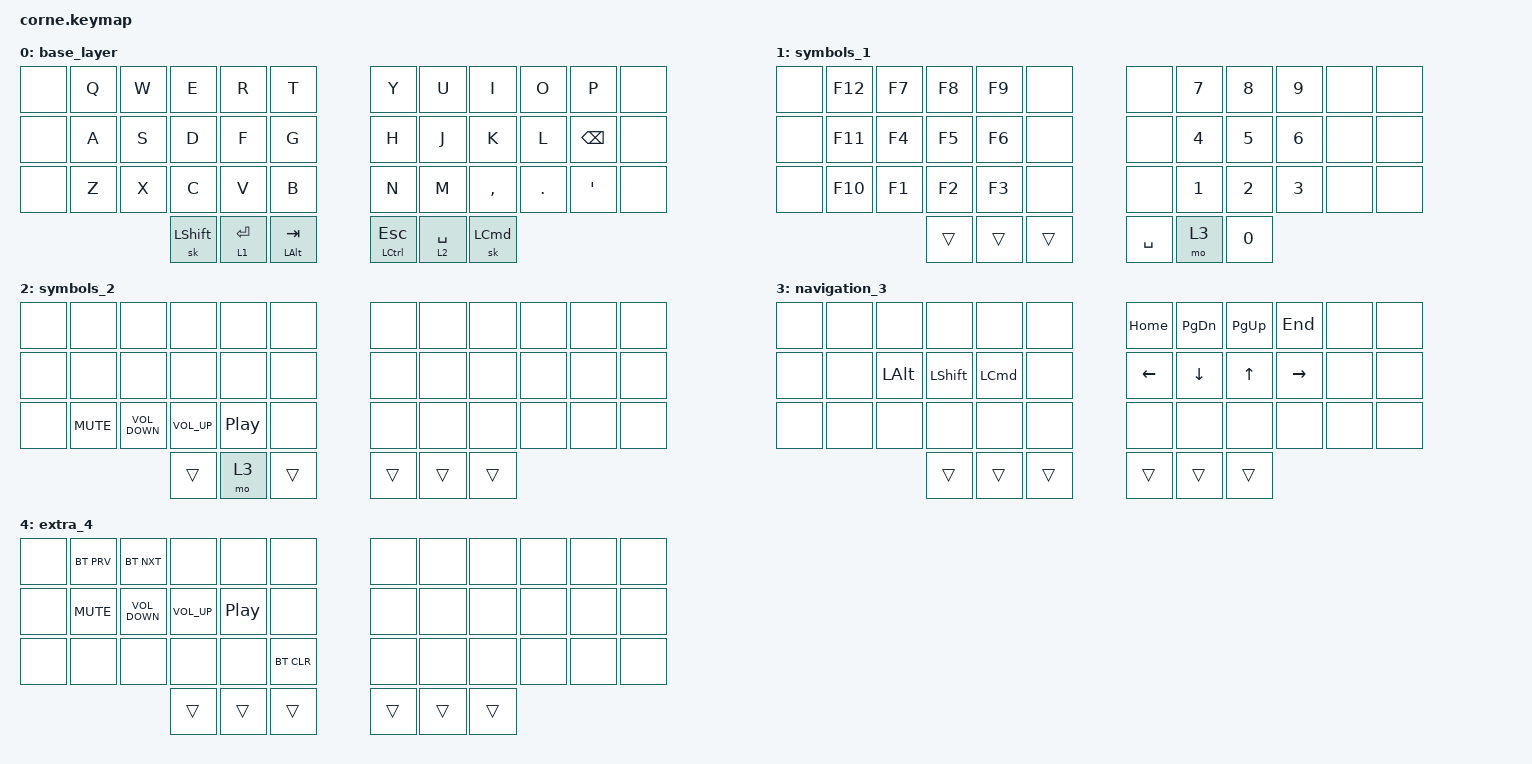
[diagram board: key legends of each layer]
/*
 *
 * SPDX-License-Identifier: MIT
 * test
 */

#include <behaviors.dtsi>
#include <dt-bindings/zmk/keys.h>
#include <dt-bindings/zmk/bt.h>
#include <dt-bindings/zmk/mouse.h>

&mmv {
  time-to-max-speed-ms = <400>;
  acceleration-exponent = <0>;
  delay-ms = <0>;
};

#define U_MOUSE_MOVE_MAX 1400

#undef MOVE_UP
#undef MOVE_DOWN
#undef MOVE_LEFT
#undef MOVE_RIGHT
#define MOVE_UP MOVE_VERT(-U_MOUSE_MOVE_MAX)
#define MOVE_DOWN MOVE_VERT(U_MOUSE_MOVE_MAX)
#define MOVE_LEFT MOVE_HOR(-U_MOUSE_MOVE_MAX)
#define MOVE_RIGHT MOVE_HOR(U_MOUSE_MOVE_MAX)

/ {
    macros {
        option_backspace: option_backspace {
            compatible = "zmk,behavior-macro";
            label = "option_backspace";
            #binding-cells = <0>;
            wait-ms = <0>;
            bindings =
                <&macro_press &kp LEFT_ALT>,
                <&macro_tap &kp BACKSPACE>,
                <&macro_release &kp LEFT_ALT>;
        };

        option_delete: option_delete {
            compatible = "zmk,behavior-macro";
            label = "option_delete";
            #binding-cells = <0>;
	        wait-ms = <0>;
            bindings =
                <&macro_press &kp LEFT_ALT>,
                <&macro_tap &kp DELETE>,
                <&macro_release &kp LEFT_ALT>;
        };

    	command_backspace: command_backspace{
            compatible = "zmk,behavior-macro";
            label = "command_backspace";
            #binding-cells = <0>;
            wait-ms = <0>;
            bindings =
                <&macro_press &kp LEFT_COMMAND>,
                <&macro_tap &kp BACKSPACE>,
                <&macro_release &kp LEFT_COMMAND>;
        };

	    command_delete: command_delete{
            compatible = "zmk,behavior-macro";
            label = "command_delete";
            #binding-cells = <0>;
            wait-ms = <0>;
            bindings =
                <&macro_press &kp LEFT_COMMAND>,
                <&macro_tap &kp DELETE>,
                <&macro_release &kp LEFT_COMMAND>;
        };

        com_tab: com_tab {
            compatible = "zmk,behavior-macro";
            label = "com_tab";
            #binding-cells = <0>;
            wait-ms = <0>;
            bindings =
                <&macro_press &kp LEFT_COMMAND>,
                <&macro_tap &kp TAB>,
                <&macro_release &kp LEFT_COMMAND>;
        };

        opt_lctrl: opt_lctrl {
            compatible = "zmk,behavior-macro";
            label = "opt_lctrl";
            #binding-cells = <0>;
            bindings =
                <&macro_press &kp LEFT_CONTROL &kp LEFT_ALT>,
                <&macro_pause_for_release>,
                <&macro_release &kp LEFT_CONTROL &kp LEFT_ALT>;
        };

        opt_com_lctrl: opt_com_lctrl {
            compatible = "zmk,behavior-macro";
            label = "opt_com_lctrl";
            #binding-cells = <0>;
            bindings =
                <&macro_press &kp LEFT_ALT &kp LEFT_COMMAND &kp LEFT_CONTROL>,
                <&macro_pause_for_release>,	
                <&macro_release &kp LEFT_ALT &kp LEFT_COMMAND &kp LEFT_CONTROL>;
        };

        opt_cmd_f: opt_cmd_f {
            compatible = "zmk,behavior-macro";
            label = "opt_cmd_f";
            #binding-cells = <0>;
            wait-ms = <0>;
            bindings =
                <&macro_press &kp LEFT_ALT &kp LEFT_COMMAND>,
                <&macro_tap &kp F>,
                <&macro_release &kp LEFT_ALT &kp LEFT_COMMAND>;
        };

        opt_com_larrow: opt_com_larrow {
            compatible = "zmk,behavior-macro";
            label = "opt_com_larrow";
            #binding-cells = <0>;
            wait-ms = <0>;
            bindings =
                <&macro_press &kp LEFT_ALT &kp LEFT_COMMAND>,
                <&macro_tap &kp LEFT_ARROW>,
                <&macro_release &kp LEFT_ALT &kp LEFT_COMMAND>;
        };

        com_enter: com_enter {
            compatible = "zmk,behavior-macro";
            label = "com_enter";
            #binding-cells = <0>;
            wait-ms = <0>;
            bindings =
                <&macro_press &kp LEFT_COMMAND>,
                <&macro_tap &kp ENTER>,
                <&macro_release &kp LEFT_COMMAND>;
        };

        com_grave: com_grave {
            compatible = "zmk,behavior-macro";
            label = "com_grave";
            #binding-cells = <0>;
            wait-ms = <0>;
            bindings =
                <&macro_press &kp LEFT_COMMAND>,
                <&macro_tap &kp GRAVE>,
                <&macro_release &kp LEFT_COMMAND>;
        };

        opt_com_rarrow: opt_com_rarrow {
            compatible = "zmk,behavior-macro";
            label = "opt_com_rarrow";
            #binding-cells = <0>;
            wait-ms = <0>;
            bindings =
                <&macro_press &kp LEFT_ALT &kp LEFT_COMMAND>,
                <&macro_tap &kp RIGHT_ARROW>,
                <&macro_release &kp LEFT_ALT &kp LEFT_COMMAND>;
        };

        cmd_shift_a: cmd_shift_a {
            compatible = "zmk,behavior-macro";
            label = "cmd_shift_a";
            #binding-cells = <0>;
            wait-ms = <0>;
            bindings =
                <&macro_press &kp LEFT_COMMAND &kp LSHIFT>,
                <&macro_tap &kp A>,
                <&macro_release &kp LEFT_COMMAND &kp LSHIFT>;
        };

        cmd_shift_p: cmd_shift_p {
                    compatible = "zmk,behavior-macro";
                    label = "cmd_shift_p";
                    #binding-cells = <0>;
                    wait-ms = <0>;
                    bindings =
                        <&macro_press &kp LEFT_COMMAND &kp LSHIFT>,
                        <&macro_tap &kp P>,
                        <&macro_release &kp LEFT_COMMAND &kp LSHIFT>;
            };

        cmd_m_bs: cmd_m_bs {
                    compatible = "zmk,behavior-macro";
                    label = "cmd_m_bs";
                    #binding-cells = <0>;
                    wait-ms = <0>;
                    bindings =
                        <&macro_press &kp LEFT_COMMAND>,
                        <&macro_tap &kp M &kp BACKSPACE>,
                        <&macro_release &kp LEFT_COMMAND>;
            };

        cmd_m_p: cmd_m_p {
                    compatible = "zmk,behavior-macro";
                    label = "cmd_m_p";
                    #binding-cells = <0>;
                    wait-ms = <0>;
                    bindings =
                        <&macro_press &kp LEFT_COMMAND>,
                        <&macro_tap &kp M &kp P>,
                        <&macro_release &kp LEFT_COMMAND>;
            };

        forward_slash: forward_slash {
                        compatible = "zmk,behavior-macro";
                        label = "forward_slash";
                        #binding-cells = <0>;
                        wait-ms = <0>;
                        bindings =
                            <&macro_tap &kp SLASH>;
            };

        mc_1: mc_1 {
            compatible = "zmk,behavior-macro";
            label = "mc_1";
            #binding-cells = <0>;
            wait-ms = <0>;
            bindings =
                <&macro_press &kp LEFT_CONTROL &kp LEFT_ALT &kp LEFT_COMMAND &kp LSHIFT>,
                <&macro_tap &kp F1>,
                <&macro_release &kp LEFT_CONTROL &kp LEFT_ALT &kp LEFT_COMMAND &kp LSHIFT>;
        };

        mc_2: mc_2 {
            compatible = "zmk,behavior-macro";
            label = "mc_2";
            #binding-cells = <0>;
            wait-ms = <0>;
            bindings =
                <&macro_press &kp LEFT_CONTROL &kp LEFT_ALT &kp LEFT_COMMAND &kp LSHIFT>,
                <&macro_tap &kp F2>,
                <&macro_release &kp LEFT_CONTROL &kp LEFT_ALT &kp LEFT_COMMAND &kp LSHIFT>;
        };

        mc_3: mc_3 {
            compatible = "zmk,behavior-macro";
            label = "mc_3";
            #binding-cells = <0>;
            wait-ms = <0>;
            bindings =
                <&macro_press &kp LEFT_CONTROL &kp LEFT_ALT &kp LEFT_COMMAND &kp LSHIFT>,
                <&macro_tap &kp F3>,
                <&macro_release &kp LEFT_CONTROL &kp LEFT_ALT &kp LEFT_COMMAND &kp LSHIFT>;
        };

        mc_4: mc_4 {
            compatible = "zmk,behavior-macro";
            label = "mc_4";
            #binding-cells = <0>;
            wait-ms = <0>;
            bindings =
                <&macro_press &kp LEFT_CONTROL &kp LEFT_ALT &kp LEFT_COMMAND &kp LSHIFT>,
                <&macro_tap &kp F4>,
                <&macro_release &kp LEFT_CONTROL &kp LEFT_ALT &kp LEFT_COMMAND &kp LSHIFT>;
        };	

        command_1: command_1 {
            compatible = "zmk,behavior-macro";
            label = "command_1";
            #binding-cells = <0>;
            wait-ms = <0>;
            bindings =
                <&macro_press &kp LEFT_COMMAND>,
                <&macro_tap &kp NUMBER_1>,
                <&macro_release &kp LEFT_COMMAND>;
        };

        command_2: command_2 {
            compatible = "zmk,behavior-macro";
            label = "command_2";
            #binding-cells = <0>;
            wait-ms = <0>;
            bindings =
                <&macro_press &kp LEFT_COMMAND>,
                <&macro_tap &kp NUMBER_2>,
                <&macro_release &kp LEFT_COMMAND>;
        };

        command_3: command_3 {
            compatible = "zmk,behavior-macro";
            label = "command_3";
            #binding-cells = <0>;
            wait-ms = <0>;
            bindings =
                <&macro_press &kp LEFT_COMMAND>,
                <&macro_tap &kp NUMBER_3>,
                <&macro_release &kp LEFT_COMMAND>;
        };

        command_4: command_4 {
            compatible = "zmk,behavior-macro";
            label = "command_4";
            #binding-cells = <0>;
            wait-ms = <0>;
            bindings =
                <&macro_press &kp LEFT_COMMAND>,
                <&macro_tap &kp NUMBER_4>,
                <&macro_release &kp LEFT_COMMAND>;
        };	
    };

    combos {
        compatible = "zmk,combos";
	
        left_parenthesis {
            bindings = <&kp LEFT_PARENTHESIS>;
            key-positions = <14 15 16>;
        };
	
        right_parenthesis {
            bindings = <&kp RIGHT_PARENTHESIS>;
            key-positions = <19 20 21>;
        };

        left_bracket {
            bindings = <&kp LEFT_BRACKET>;
            key-positions = <26 27 28>;
        };
	
        right_bracket {
            bindings = <&kp RIGHT_BRACKET>;
            key-positions = <31 32 33>;
        };

        plus {
            bindings = <&kp PLUS>;
            key-positions = <8 9 10>;
        };
	
        equal {
            bindings = <&kp EQUAL>;
            key-positions = <7 8 9>;
        };

        minus {
            bindings = <&kp MINUS>;
            key-positions = <1 2 3>;
        };
	
        underscore {
            bindings = <&kp UNDERSCORE>;
            key-positions = <2 3 4>;
        };

        colon {
            bindings = <&kp COLON>;
            key-positions = <32 33 34>;
        };
	
        semicolon {
            bindings = <&kp SEMICOLON>;
            key-positions = <25 26 27>;
        };
	
        opt_backspace{
            bindings = <&option_backspace>;
            key-positions = <13 14 15>;
        };
 	
        opt_delete{
            bindings = <&option_delete>;
            key-positions = <20 21 22>;
        };

        backslash{
            bindings = <&kp BACKSLASH>;
            key-positions = <25 26 27 28>;
        };   

        slash{
            bindings = <&kp SLASH>;
            key-positions = <31 32 33 34>;
        };   

    	question{
            bindings = <&kp QUESTION>;
            key-positions = <13 14 15 16>;
        };   

        exclamation{
            bindings = <&kp EXCL>;
            key-positions = <19 20 21 22>;
        };   

    };

    keymap {
        compatible = "zmk,keymap";

        base_layer {
            bindings = <
                &none &kp Q           &kp W            &kp E          &kp R            &kp T            &kp Y              &kp U          &kp I         &kp O                &kp P                 &none
                &none &kp A           &kp S            &kp D          &kp F            &kp G            &kp H              &kp J          &kp K         &kp L                &kp BACKSPACE         &none
                &none &kp Z           &kp X            &kp C          &kp V            &kp B            &kp N              &kp M          &kp COMMA     &kp DOT              &kp SINGLE_QUOTE      &none
                                                       &sk LSHIFT     &lt 1 ENTER      &mt LEFT_ALT TAB &mt LEFT_CONTROL ESC &lt 2 SPACE  &sk LEFT_COMMAND
            >;
        };

        symbols_1 {
            bindings = <
                &none &kp F12         &kp F7           &kp F8         &kp F9           &none             &none             &kp NUMBER_7   &kp NUMBER_8  &kp NUMBER_9         &none                 &none
                &none &kp F11         &kp F4           &kp F5         &kp F6           &none             &none             &kp NUMBER_4   &kp NUMBER_5  &kp NUMBER_6         &none                 &none
                &none &kp F10         &kp F1           &kp F2         &kp F3           &none             &none             &kp NUMBER_1   &kp NUMBER_2  &kp NUMBER_3         &none                 &none
                                                       &trans         &trans           &trans            &kp SPACE         &mo 3          &kp NUMBER_0
            >; 
        };

        symbols_2 {
            bindings = <
                &none &none            &none            &none          &none            &none             &none             &none          &none         &none                &none                 &none
                &none &none            &none            &none          &none            &none             &none             &none          &none         &none                &none                 &none
                &none &kp C_MUTE       &kp C_VOLUME_DOWN&kp C_VOLUME_UP&kp C_PLAY_PAUSE &none             &none             &none          &none         &none                &none                 &none
                                                        &trans         &mo 3            &trans            &trans            &trans         &trans
            >;
        };

        navigation_3 {
            bindings = <
                &none &none           &none            &none          &none            &none             &kp HOME          &kp PAGE_DOWN  &kp PAGE_UP   &kp END              &none                 &none
                &none &none           &kp LEFT_ALT     &kp LEFT_SHIFT &kp LEFT_COMMAND &none             &kp LEFT_ARROW    &kp DOWN_ARROW &kp UP_ARROW  &kp RIGHT_ARROW      &none                 &none
                &none &none           &none            &none          &none            &none             &none             &none          &none         &none                &none                 &none
                                                       &trans         &trans           &trans            &trans            &trans         &trans
            >;
        };

        extra_4 {
            bindings = <
                &none &bt BT_PRV      &bt BT_NXT       &none          &none            &none             &none             &none          &none         &none                &none                 &none
                &none &kp C_MUTE      &kp C_VOLUME_DOWN&kp C_VOLUME_UP&kp C_PLAY_PAUSE &none             &none             &none          &none         &none                &none                 &none
                &none &none           &none            &none          &none            &bt BT_CLR        &none             &none          &none         &none                &none                 &none
                                                       &trans         &trans           &trans            &trans            &trans         &trans
            >;
        };
    };
};
